# iom480ae register map
Registers are 32-bit, access not given, no defined reset value unless marked. A register's access mark holds for its fields unless they carry their own. Addresses are absolute; registers are grouped by the start of their names; [hi:lo] are bit positions; {n}, {i} and the like mark numbered series.

## BPWM0
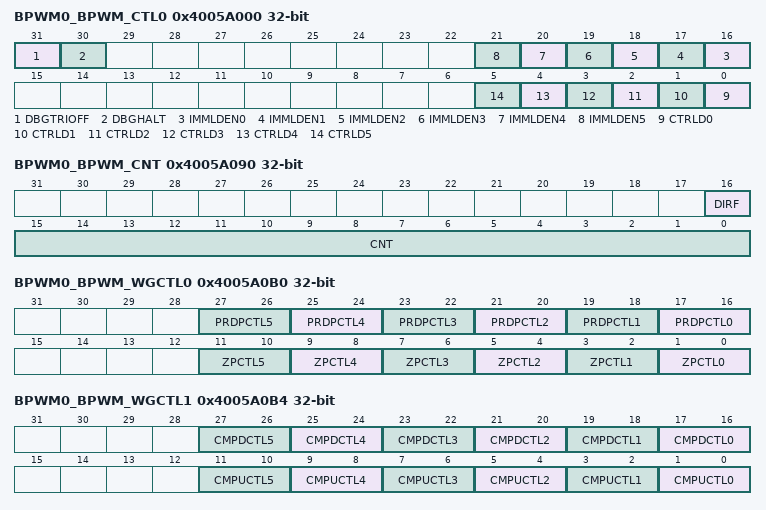
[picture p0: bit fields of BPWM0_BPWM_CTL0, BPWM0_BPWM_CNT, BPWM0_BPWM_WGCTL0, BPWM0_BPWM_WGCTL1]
0x4005A000 BPWM0_BPWM_CTL0
  [31] DBGTRIOFF, [30] DBGHALT, [n+16] IMMLDEN{n} (n=0..5), [n] CTRLD{n} (n=0..5)
0x4005A004 BPWM0_BPWM_CTL1
  [1:0] CNTTYPE0
0x4005A010 BPWM0_BPWM_CLKSRC
  [2:0] ECLKSRC0
0x4005A014 BPWM0_BPWM_CLKPSC
  [11:0] CLKPSC
0x4005A020 BPWM0_BPWM_CNTEN
  [0] CNTEN0
0x4005A024 BPWM0_BPWM_CNTCLR
  [0] CNTCLR0
0x4005A030 BPWM0_BPWM_PERIOD
  [15:0] PERIOD
{0x4005A050+4i} BPWM0_BPWM_CMPDAT{i} (i=0..5)
  [15:0] CMPDAT
0x4005A090 BPWM0_BPWM_CNT
  [16] DIRF, [15:0] CNT
0x4005A0B0 BPWM0_BPWM_WGCTL0
  [2n+17:2n+16] PRDPCTL{n} (n=0..5), [2n+1:2n] ZPCTL{n} (n=0..5)
0x4005A0B4 BPWM0_BPWM_WGCTL1
  [2n+17:2n+16] CMPDCTL{n} (n=0..5), [2n+1:2n] CMPUCTL{n} (n=0..5)
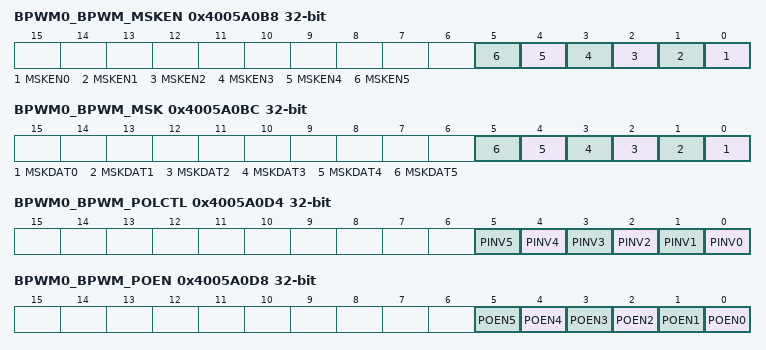
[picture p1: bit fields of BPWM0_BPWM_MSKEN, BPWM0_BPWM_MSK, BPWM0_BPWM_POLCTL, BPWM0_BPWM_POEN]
0x4005A0B8 BPWM0_BPWM_MSKEN
  [n] MSKEN{n} (n=0..5)
0x4005A0BC BPWM0_BPWM_MSK
  [n] MSKDAT{n} (n=0..5)
0x4005A0D4 BPWM0_BPWM_POLCTL
  [n] PINV{n} (n=0..5)
0x4005A0D8 BPWM0_BPWM_POEN
  [n] POEN{n} (n=0..5)
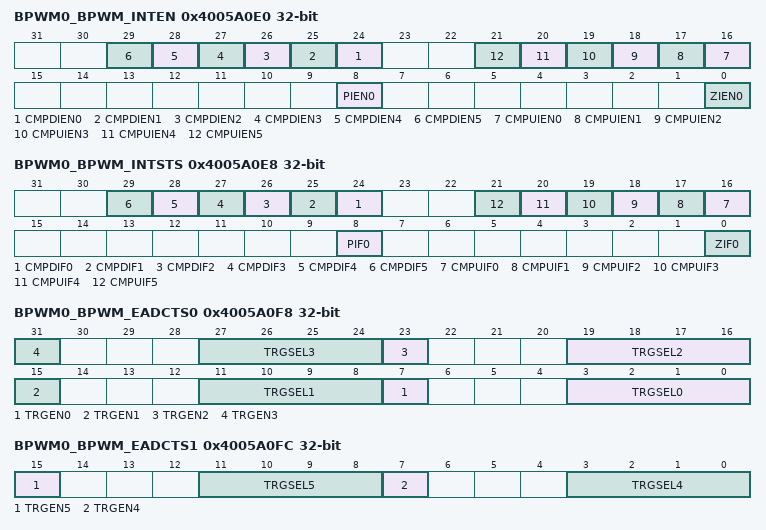
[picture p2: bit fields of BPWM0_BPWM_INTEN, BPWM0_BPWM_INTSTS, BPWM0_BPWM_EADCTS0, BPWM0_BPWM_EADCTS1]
0x4005A0E0 BPWM0_BPWM_INTEN
  [n+24] CMPDIEN{n} (n=0..5), [n+16] CMPUIEN{n} (n=0..5), [8] PIEN0, [0] ZIEN0
0x4005A0E8 BPWM0_BPWM_INTSTS
  [n+24] CMPDIF{n} (n=0..5), [n+16] CMPUIF{n} (n=0..5), [8] PIF0, [0] ZIF0
0x4005A0F8 BPWM0_BPWM_EADCTS0
  [8n+7] TRGEN{n} (n=0..3), [8n+3:8n] TRGSEL{n} (n=0..3)
0x4005A0FC BPWM0_BPWM_EADCTS1
  [15] TRGEN5, [11:8] TRGSEL5, [7] TRGEN4, [3:0] TRGSEL4
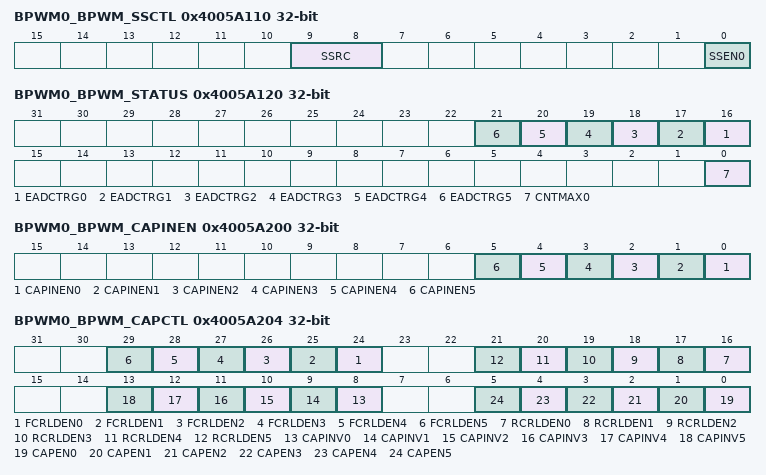
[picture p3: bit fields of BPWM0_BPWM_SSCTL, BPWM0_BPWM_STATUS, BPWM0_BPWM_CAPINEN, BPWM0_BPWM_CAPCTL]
0x4005A110 BPWM0_BPWM_SSCTL
  [9:8] SSRC, [0] SSEN0
0x4005A114 BPWM0_BPWM_SSTRG
  [0] CNTSEN
0x4005A120 BPWM0_BPWM_STATUS
  [n+16] EADCTRG{n} (n=0..5), [0] CNTMAX0
0x4005A200 BPWM0_BPWM_CAPINEN
  [n] CAPINEN{n} (n=0..5)
0x4005A204 BPWM0_BPWM_CAPCTL
  [n+24] FCRLDEN{n} (n=0..5), [n+16] RCRLDEN{n} (n=0..5), [n+8] CAPINV{n} (n=0..5), [n] CAPEN{n} (n=0..5)
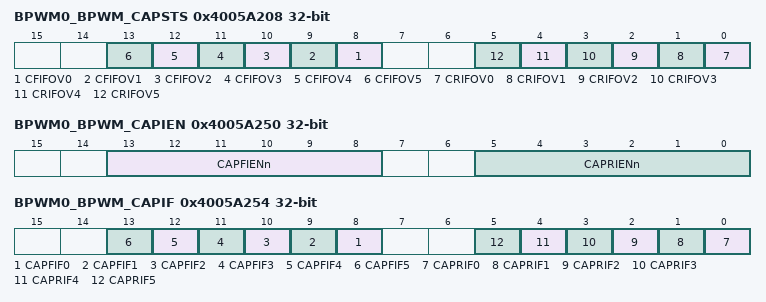
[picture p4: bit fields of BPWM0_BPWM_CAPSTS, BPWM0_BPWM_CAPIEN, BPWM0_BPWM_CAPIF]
0x4005A208 BPWM0_BPWM_CAPSTS
  [n+8] CFIFOV{n} (n=0..5), [n] CRIFOV{n} (n=0..5)
{0x4005A20C+8i} BPWM0_BPWM_RCAPDAT{i} (i=0..5)
  [15:0] RCAPDAT
{0x4005A210+8i} BPWM0_BPWM_FCAPDAT{i} (i=0..5)
  [15:0] FCAPDAT
0x4005A250 BPWM0_BPWM_CAPIEN
  [13:8] CAPFIENn, [5:0] CAPRIENn
0x4005A254 BPWM0_BPWM_CAPIF
  [n+8] CAPFIF{n} (n=0..5), [n] CAPRIF{n} (n=0..5)
0x4005A304 BPWM0_BPWM_PBUF
  [15:0] PBUF
{0x4005A31C+4i} BPWM0_BPWM_CMPBUF{i} (i=0..5)
  [15:0] CMPBUF

## BPWM1
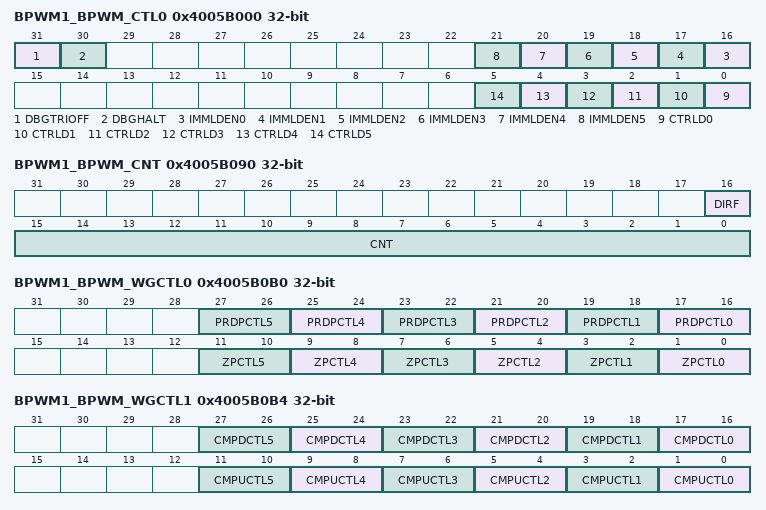
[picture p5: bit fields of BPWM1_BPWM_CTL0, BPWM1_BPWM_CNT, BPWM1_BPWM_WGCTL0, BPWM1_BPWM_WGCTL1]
0x4005B000 BPWM1_BPWM_CTL0
  [31] DBGTRIOFF, [30] DBGHALT, [n+16] IMMLDEN{n} (n=0..5), [n] CTRLD{n} (n=0..5)
0x4005B004 BPWM1_BPWM_CTL1
  [1:0] CNTTYPE0
0x4005B010 BPWM1_BPWM_CLKSRC
  [2:0] ECLKSRC0
0x4005B014 BPWM1_BPWM_CLKPSC
  [11:0] CLKPSC
0x4005B020 BPWM1_BPWM_CNTEN
  [0] CNTEN0
0x4005B024 BPWM1_BPWM_CNTCLR
  [0] CNTCLR0
0x4005B030 BPWM1_BPWM_PERIOD
  [15:0] PERIOD
{0x4005B050+4i} BPWM1_BPWM_CMPDAT{i} (i=0..5)
  [15:0] CMPDAT
0x4005B090 BPWM1_BPWM_CNT
  [16] DIRF, [15:0] CNT
0x4005B0B0 BPWM1_BPWM_WGCTL0
  [2n+17:2n+16] PRDPCTL{n} (n=0..5), [2n+1:2n] ZPCTL{n} (n=0..5)
0x4005B0B4 BPWM1_BPWM_WGCTL1
  [2n+17:2n+16] CMPDCTL{n} (n=0..5), [2n+1:2n] CMPUCTL{n} (n=0..5)
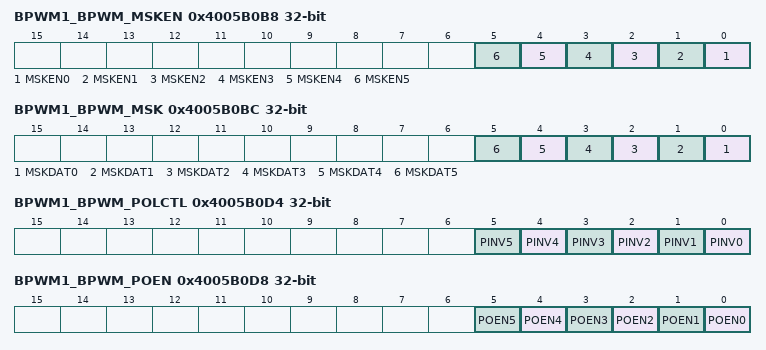
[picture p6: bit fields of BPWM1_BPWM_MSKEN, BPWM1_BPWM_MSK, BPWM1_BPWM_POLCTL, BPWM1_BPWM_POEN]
0x4005B0B8 BPWM1_BPWM_MSKEN
  [n] MSKEN{n} (n=0..5)
0x4005B0BC BPWM1_BPWM_MSK
  [n] MSKDAT{n} (n=0..5)
0x4005B0D4 BPWM1_BPWM_POLCTL
  [n] PINV{n} (n=0..5)
0x4005B0D8 BPWM1_BPWM_POEN
  [n] POEN{n} (n=0..5)
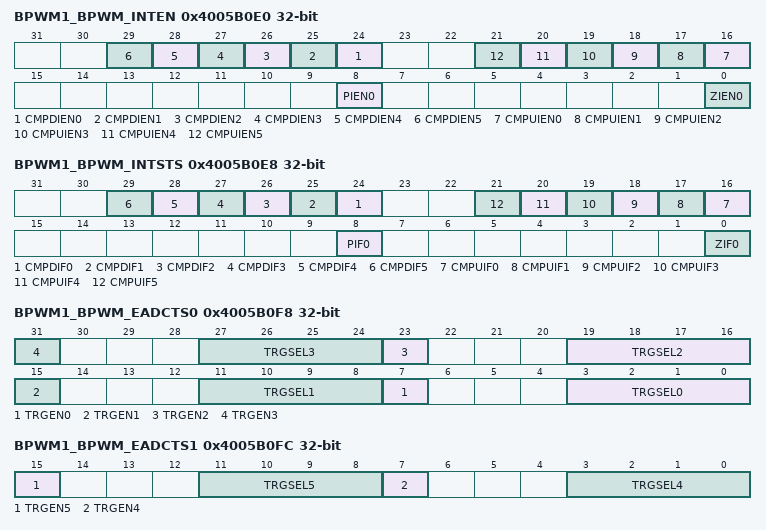
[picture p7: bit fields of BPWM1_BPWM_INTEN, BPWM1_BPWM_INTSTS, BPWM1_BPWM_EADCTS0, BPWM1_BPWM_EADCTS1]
0x4005B0E0 BPWM1_BPWM_INTEN
  [n+24] CMPDIEN{n} (n=0..5), [n+16] CMPUIEN{n} (n=0..5), [8] PIEN0, [0] ZIEN0
0x4005B0E8 BPWM1_BPWM_INTSTS
  [n+24] CMPDIF{n} (n=0..5), [n+16] CMPUIF{n} (n=0..5), [8] PIF0, [0] ZIF0
0x4005B0F8 BPWM1_BPWM_EADCTS0
  [8n+7] TRGEN{n} (n=0..3), [8n+3:8n] TRGSEL{n} (n=0..3)
0x4005B0FC BPWM1_BPWM_EADCTS1
  [15] TRGEN5, [11:8] TRGSEL5, [7] TRGEN4, [3:0] TRGSEL4
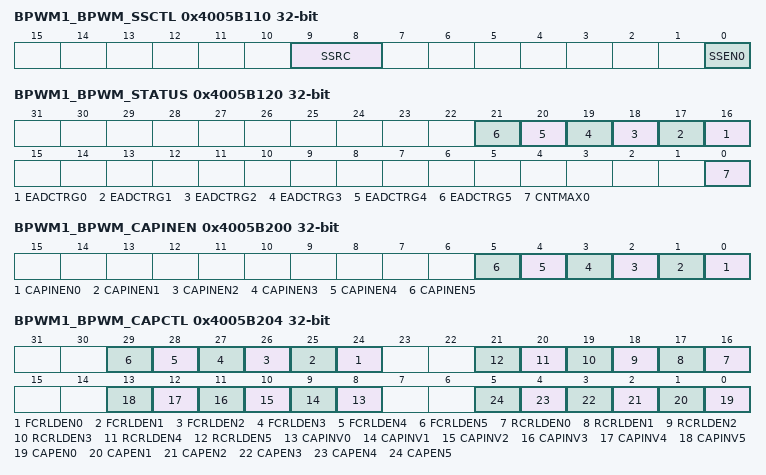
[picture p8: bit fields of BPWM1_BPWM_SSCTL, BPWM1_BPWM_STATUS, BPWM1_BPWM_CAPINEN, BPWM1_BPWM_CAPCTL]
0x4005B110 BPWM1_BPWM_SSCTL
  [9:8] SSRC, [0] SSEN0
0x4005B114 BPWM1_BPWM_SSTRG
  [0] CNTSEN
0x4005B120 BPWM1_BPWM_STATUS
  [n+16] EADCTRG{n} (n=0..5), [0] CNTMAX0
0x4005B200 BPWM1_BPWM_CAPINEN
  [n] CAPINEN{n} (n=0..5)
0x4005B204 BPWM1_BPWM_CAPCTL
  [n+24] FCRLDEN{n} (n=0..5), [n+16] RCRLDEN{n} (n=0..5), [n+8] CAPINV{n} (n=0..5), [n] CAPEN{n} (n=0..5)
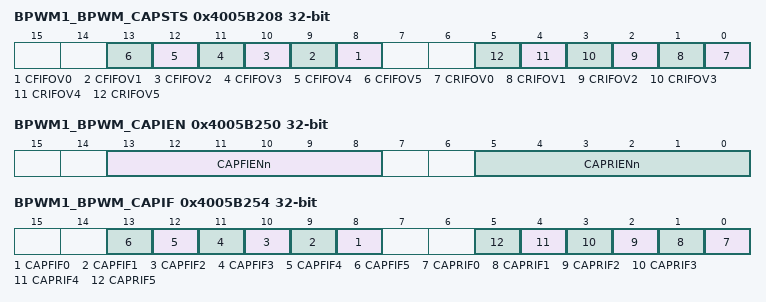
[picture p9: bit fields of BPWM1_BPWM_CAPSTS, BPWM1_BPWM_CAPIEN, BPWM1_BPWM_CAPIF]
0x4005B208 BPWM1_BPWM_CAPSTS
  [n+8] CFIFOV{n} (n=0..5), [n] CRIFOV{n} (n=0..5)
{0x4005B20C+8i} BPWM1_BPWM_RCAPDAT{i} (i=0..5)
  [15:0] RCAPDAT
{0x4005B210+8i} BPWM1_BPWM_FCAPDAT{i} (i=0..5)
  [15:0] FCAPDAT
0x4005B250 BPWM1_BPWM_CAPIEN
  [13:8] CAPFIENn, [5:0] CAPRIENn
0x4005B254 BPWM1_BPWM_CAPIF
  [n+8] CAPFIF{n} (n=0..5), [n] CAPRIF{n} (n=0..5)
0x4005B304 BPWM1_BPWM_PBUF
  [15:0] PBUF
{0x4005B31C+4i} BPWM1_BPWM_CMPBUF{i} (i=0..5)
  [15:0] CMPBUF
